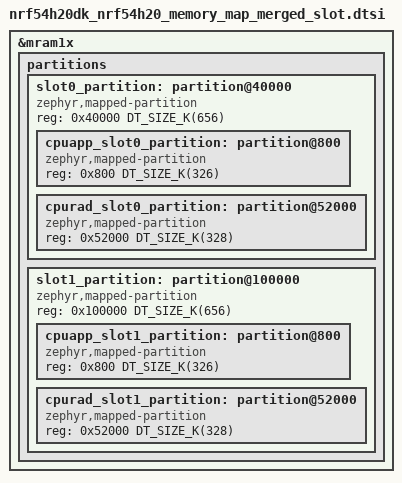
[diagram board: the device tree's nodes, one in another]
/*
 * Copyright (c) 2025 Nordic Semiconductor ASA
 *
 * SPDX-License-Identifier: LicenseRef-Nordic-5-Clause
 */

/delete-node/ &cpuapp_slot0_partition;
/delete-node/ &cpuapp_slot1_partition;
/delete-node/ &cpurad_slot0_partition;
/delete-node/ &cpurad_slot1_partition;

&mram1x {
	partitions {
		slot0_partition: partition@40000 {
			compatible = "zephyr,mapped-partition";
			reg = <0x40000 DT_SIZE_K(656)>;
			ranges = <0x0 0x40000 DT_SIZE_K(656)>;
			#address-cells = <1>;
			#size-cells = <1>;

			cpuapp_slot0_partition: partition@800 {
				compatible = "zephyr,mapped-partition";
				reg = <0x800 DT_SIZE_K(326)>;
			};

			cpurad_slot0_partition: partition@52000 {
				compatible = "zephyr,mapped-partition";
				reg = <0x52000 DT_SIZE_K(328)>;
			};
		};

		slot1_partition: partition@100000 {
			compatible = "zephyr,mapped-partition";
			reg = <0x100000 DT_SIZE_K(656)>;
			ranges = <0x0 0x100000 DT_SIZE_K(656)>;
			#address-cells = <1>;
			#size-cells = <1>;

			cpuapp_slot1_partition: partition@800 {
				compatible = "zephyr,mapped-partition";
				reg = <0x800 DT_SIZE_K(326)>;
			};

			cpurad_slot1_partition: partition@52000 {
				compatible = "zephyr,mapped-partition";
				reg = <0x52000 DT_SIZE_K(328)>;
			};
		};
	};
};
